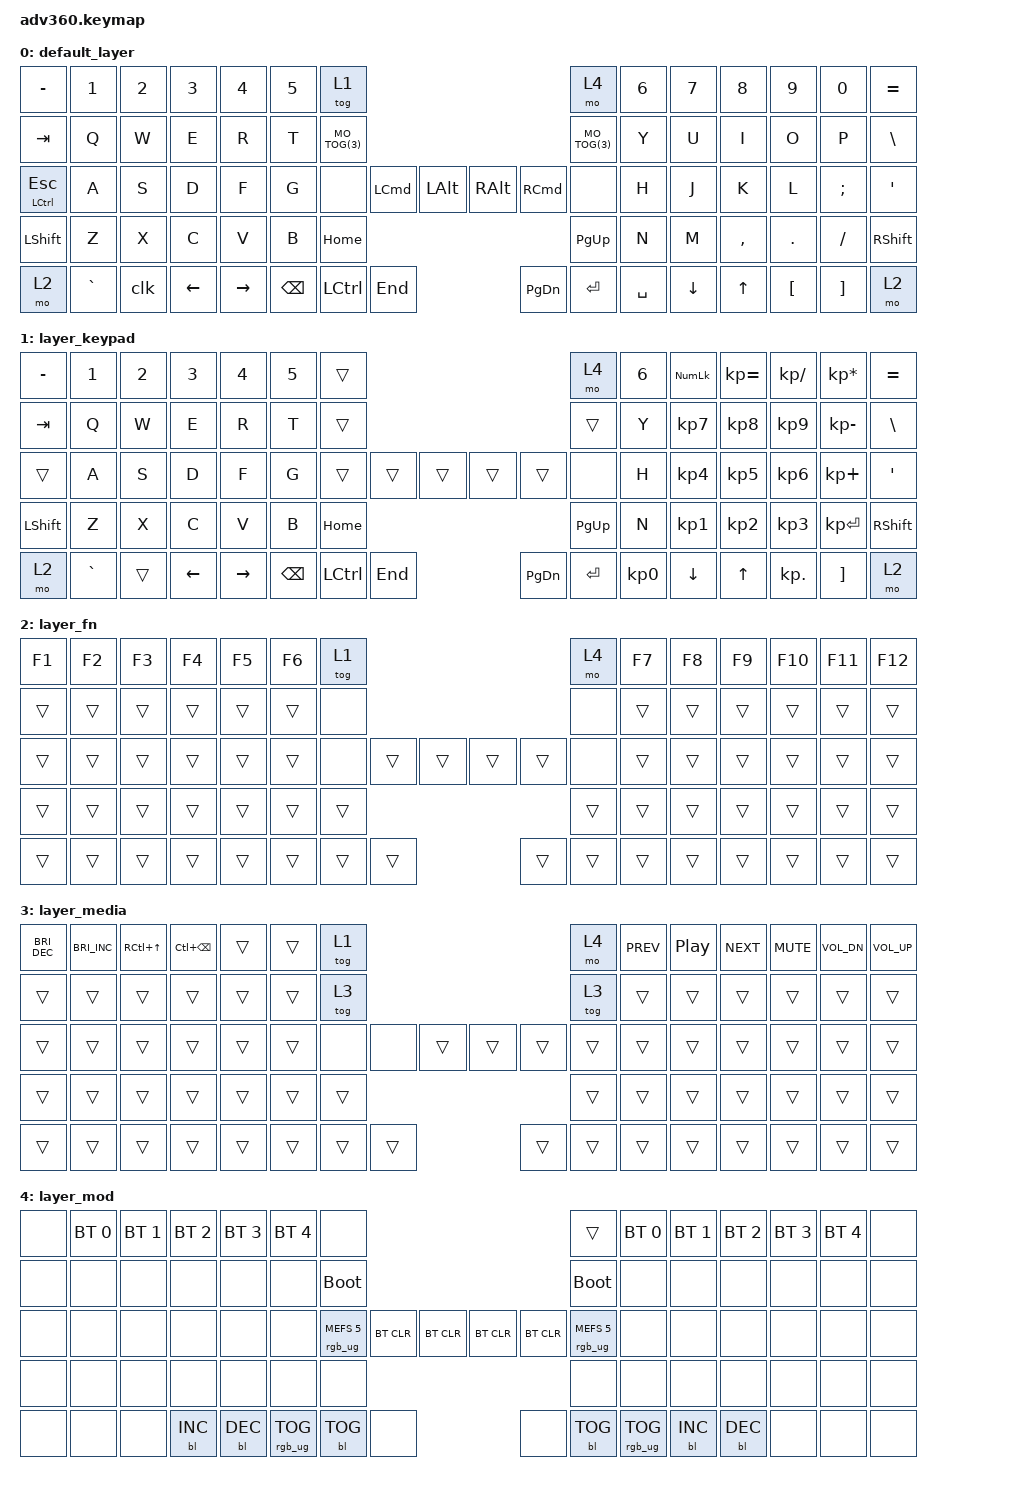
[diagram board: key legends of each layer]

/*
 * Copyright (c) 2020 The ZMK Contributors
 *
 * SPDX-License-Identifier: MIT
 */

#include <behaviors.dtsi>
#include <dt-bindings/zmk/keys.h>
#include <dt-bindings/zmk/bt.h>
#include <dt-bindings/zmk/rgb.h>
#include <dt-bindings/zmk/backlight.h>

&caps_word {
    continue-list = <UNDERSCORE MINUS LSHFT RSHFT BSPC>;
};

#define MO_TOG(layer) &mo_tog layer layer

/ {
  behaviors {
    #include "macros.dtsi"

    hm: homerow_mods {
        compatible = "zmk,behavior-hold-tap";
        label = "HOMEROW_MODS";
        #binding-cells = <2>;
        tapping-term-ms = <200>;
        quick_tap_ms = <175>;
        flavor = "tap-preferred";
        bindings = <&kp>, <&kp>;
    };

    mo_tog: behavior_mo_tog {
      compatible = "zmk,behavior-hold-tap";
      label = "mo_tog";
      #binding-cells = <2>;
      flavor = "hold-preferred";
      tapping-term-ms = <200>;
      bindings = <&mo>, <&tog>;
    };

    clk: behavior_clk {
      compatible = "zmk,behavior-tap-dance";
      label = "clk";
      #binding-cells = <0>;
      tapping-term-ms = <200>;
      bindings = <&caps_word>, <&kp CAPS>;
    };
  };

    keymap {
        compatible = "zmk,keymap";


        default_layer {
            bindings = <
        &kp MINUS &kp N1    &kp N2  &kp N3   &kp N4     &kp N5 &tog 1                                                              &mo 4      &kp N6 &kp N7   &kp N8    &kp N9   &kp N0   &kp EQUAL
        &kp TAB   &kp Q     &kp W   &kp E    &kp R      &kp T  MO_TOG(3)                                                           MO_TOG(3)  &kp Y  &kp U    &kp I     &kp O    &kp P    &kp BSLH
  &mt LCTRL ESC   &kp A     &kp S   &kp D    &kp F      &kp G  &none           &kp LCMD  &kp LALT  &kp RALT  &kp RCMD              &none      &kp H  &kp J     &kp K    &kp L    &kp SEMI &kp SQT
        &kp LSHFT &kp Z     &kp X   &kp C    &kp V      &kp B                            &kp HOME  &kp PG_UP                                  &kp N  &kp M    &kp COMMA &kp DOT  &kp FSLH &kp RSHFT
        &mo 2     &kp GRAVE &clk    &kp LEFT &kp RIGHT                &kp BSPC &kp LCTRL &kp END   &kp PG_DN &kp ENTER &kp SPACE                     &kp DOWN &kp UP    &kp LBKT &kp RBKT &mo 2
            >;
        };

        layer_keypad {
            bindings = <
        &kp MINUS &kp N1    &kp N2     &kp N3   &kp N4     &kp N5 &trans                                                            &mo 4  &kp N6 &kp KP_NUM &kp KP_EQUAL &kp KP_DIVIDE &kp KP_MULTIPLY &kp EQUAL
        &kp TAB   &kp Q     &kp W      &kp E    &kp R      &kp T  &trans                                                            &trans &kp Y  &kp KP_N7  &kp KP_N8    &kp KP_N9     &kp KP_MINUS    &kp BSLH
        &trans    &kp A     &kp S      &kp D    &kp F      &kp G  &trans          &trans    &trans    &trans    &trans              &none  &kp H  &kp KP_N4  &kp KP_N5    &kp KP_N6     &kp KP_PLUS     &kp SQT
        &kp LSHFT &kp Z     &kp X      &kp C    &kp V      &kp B                            &kp HOME  &kp PG_UP                            &kp N  &kp KP_N1  &kp KP_N2    &kp KP_N3     &kp KP_ENTER    &kp RSHFT
        &mo 2     &kp GRAVE &trans     &kp LEFT &kp RIGHT                &kp BSPC &kp LCTRL &kp END   &kp PG_DN &kp ENTER &kp KP_N0               &kp DOWN   &kp UP       &kp KP_DOT    &kp RBKT        &mo 2
            >;
        };

        layer_fn {
            bindings = <
        &kp F1 &kp F2 &kp F3 &kp F4 &kp F5 &kp F6 &tog 1                                            &mo 4 &kp F7 &kp F8 &kp F9 &kp F10 &kp F11 &kp F12
        &trans &trans &trans &trans &trans &trans &none                                             &none &trans &trans &trans &trans  &trans  &trans
        &trans &trans &trans &trans &trans &trans &none         &trans &trans  &trans &trans        &none &trans &trans &trans &trans  &trans  &trans
        &trans &trans &trans &trans &trans &trans                      &trans  &trans                     &trans &trans &trans &trans  &trans  &trans
        &trans &trans &trans &trans &trans               &trans &trans &trans  &trans &trans &trans              &trans &trans &trans  &trans  &trans

            >;
        };

        layer_media {
            bindings = <
&kp C_BRI_DEC  &kp C_BRI_INC  &kp RC(UP)  &kp LC(BSPC)  &trans  &trans  &tog 1                                                   &mo 4   &kp C_PREV  &kp C_PLAY_PAUSE  &kp C_NEXT  &kp C_MUTE  &kp C_VOL_DN  &kp C_VOL_UP
&trans         &trans         &trans      &trans        &trans  &trans  &tog 3                                                   &tog 3  &trans      &trans            &trans      &trans      &trans        &trans
&trans         &trans         &trans      &trans        &trans  &trans  &none           &none   &trans   &trans  &trans          &trans  &trans      &trans            &trans      &trans      &trans        &trans
&trans         &trans         &trans      &trans        &trans  &trans                          &trans   &trans                          &trans      &trans            &trans      &trans      &trans        &trans
&trans         &trans         &trans      &trans        &trans                  &trans  &trans  &trans   &trans  &trans  &trans                      &trans            &trans      &trans      &trans        &trans
            >;
        };

        layer_mod {
            bindings = <
&none &bt BT_SEL 0 &bt BT_SEL 1 &bt BT_SEL 2 &bt BT_SEL 3 &bt BT_SEL 4 &none                                                                                               &trans                 &bt BT_SEL 0 &bt BT_SEL 1 &bt BT_SEL 2 &bt BT_SEL 3 &bt BT_SEL 4 &none
&none &none        &none        &none        &none        &none        &bootloader                                                                                         &bootloader            &none        &none        &none        &none        &none        &none
&none &none        &none        &none        &none        &none        &rgb_ug RGB_MEFS_CMD 5                 &bt BT_CLR &bt BT_CLR  &bt BT_CLR &bt BT_CLR                 &rgb_ug RGB_MEFS_CMD 5 &none        &none        &none        &none        &none        &none
&none &none        &none        &none        &none        &none                                                          &none       &none                                                        &none        &none        &none        &none        &none        &none
&none &none        &none        &bl BL_INC   &bl BL_DEC                                       &rgb_ug RGB_TOG &bl BL_TOG &none       &none      &bl BL_TOG &rgb_ug RGB_TOG                                     &bl BL_INC   &bl BL_DEC   &none        &none        &none

            >;
        };

    };
};
